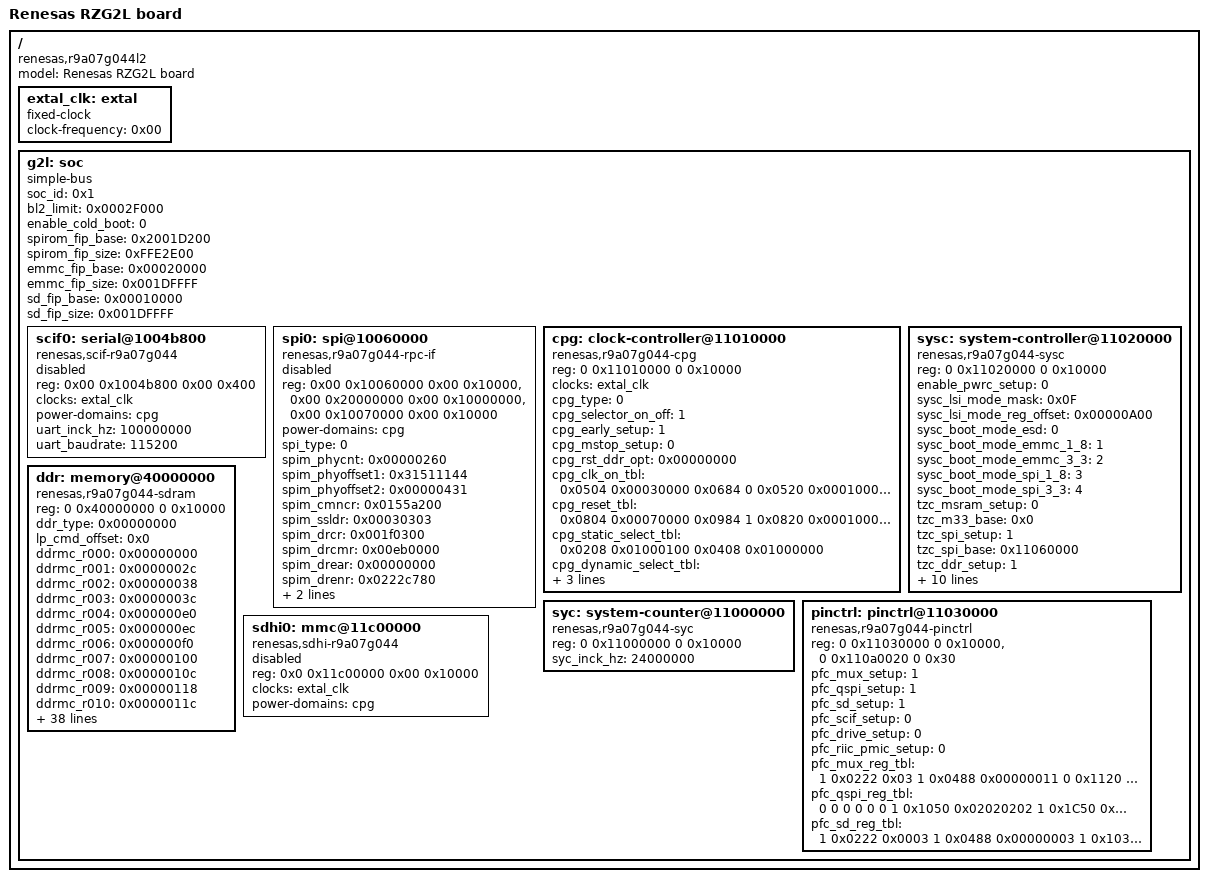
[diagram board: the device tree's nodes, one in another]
// SPDX-License-Identifier: (GPL-2.0-only OR BSD-2-Clause)
/*
 * Copyright (C) 2025 Renesas Electronics Corp.
 */

/dts-v1/;

/ {
	compatible = "renesas,r9a07g044l2", "renesas,r9a07g044";
	model = "Renesas RZG2L board";
	#address-cells = <2>;
	#size-cells = <2>;

	/* clock can be either from exclk or crystal oscillator (XIN/XOUT) */
	extal_clk: extal {
		compatible = "fixed-clock";
		#clock-cells = <0x00>;
		clock-frequency = <0x00>;
		phandle = <0x03>;
	};

	g2l: soc {
		compatible = "simple-bus";
		soc_id = <0x1>;
		bl2_limit = <0x0002F000>;
		enable_cold_boot = <0>;
		spirom_fip_base = <0x2001D200>;
		spirom_fip_size = <0xFFE2E00>;
		emmc_fip_base = <0x00020000>;
		emmc_fip_size = <0x001DFFFF>;
		sd_fip_base = <0x00010000>;
		sd_fip_size = <0x001DFFFF>;
		#address-cells = <0x02>;
		#size-cells = <0x02>;
		ranges;

		scif0: serial@1004b800 {
			compatible = "renesas,scif-r9a07g044";
			reg = <0x00 0x1004b800 0x00 0x400>;
			interrupt-names = "eri", "rxi", "txi", "bri", "dri", "tei";
			clocks = <&extal_clk>;
			clock-names = "fck";
			power-domains = <&cpg>;
			status = "disabled";

			uart_inck_hz = <100000000>;
			uart_baudrate = <115200>;
		};

		spi0: spi@10060000 {
			compatible = "renesas,r9a07g044-rpc-if", "renesas,rzg2l-rpc-if";
			reg = <0x00 0x10060000 0x00 0x10000>,
			      <0x00 0x20000000 0x00 0x10000000>,
			      <0x00 0x10070000 0x00 0x10000>;
			reg-names = "regs", "dirmap", "wbuf";
			power-domains = <&cpg>;
			#address-cells = <1>;
			#size-cells = <0>;
			status = "disabled";

			/* SPI type
			 * [0] = SPI Multi IO
			 * [1] = XSPI
			 */
			spi_type = <0>;

			/* SPI Multi IO specific settings */
			spim_phycnt = <0x00000260>;
			spim_phyoffset1 = <0x31511144>;
			spim_phyoffset2 = <0x00000431>;
			spim_cmncr = <0x0155a200>;
			spim_ssldr = <0x00030303>;
			spim_drcr = <0x001f0300>;
			spim_drcmr = <0x00eb0000>;
			spim_drear = <0x00000000>;
			spim_drenr = <0x0222c780>;
			spim_drdmcr = <0x00000003>;
			spim_drdrenr = <0x00000000>;
		};

		cpg: clock-controller@11010000 {
			compatible = "renesas,r9a07g044-cpg";
			reg = <0 0x11010000 0 0x10000>;
			clocks = <&extal_clk>;
			clock-names = "extal";
			#clock-cells = <2>;
			#reset-cells = <1>;
			#power-domain-cells = <0>;

			cpg_type = <0>;
			cpg_selector_on_off = <1>;
			cpg_early_setup = <1>;
			cpg_mstop_setup = <0>;
			cpg_rst_ddr_opt = <0x00000000>;

			cpg_clk_on_tbl = <
				0x0504 0x00030000
				0x0684
				0
				
				0x0520 0x00010000
				0x06A0
				0
				
				0x052C 0x00030003
				0x06AC
				0
				
				0x0534 0x00060000
				0x06B4
				0
				
				0x0538 0x00010000
				0x06B8
				0
				
				0x053C 0x00010000
				0x06BC
				0
				
				0x0540 0x00010000
				0x06C0
				0
				
				0x0544 0x000F0000
				0x06C4
				0
				
				0x0548 0x003C0000
				0x06C8
				0

				
				0x054C 0x00030000
				0x06CC
				0

				0x0550 0x00030003
				0x06D0
				0
				
				0x0554 0x00ff00ff
				0x06D4
				0
				
				0x0558 0x00070000
				0x06D8
				0
				
				0x055C 0x00030000
				0x06DC
				0
				
				0x0560 0x00010001
				0x06E0
				0
				
				0x0564 0x001f0000
				0x06E4
				0
				
				0x0568 0x003f0000
				0x06E8
				0
				
				0x056C 0x00030000
				0x06EC
				0
				
				0x0570 0x00ff0000
				0x06F0
				0
				
				0x0574 0x00010000
				0x06F4
				0
				
				0x0578 0x000f0000
				0x06F8
				0
				
				0x057C 0x00030000
				0x06FC
				0
				
				0x0580 0x000f0000
				0x0700
				0
				
				0x0584 0x001f0001
				0x0704
				0
				
				0x0588 0x00030000
				0x0708
				0
				
				0x058C 0x00010000
				0x070C
				0
				
				0x0590 0x00070000
				0x0710
				0
				
				0x0594 0x00010000
				0x0714
				0
				
				0x0598 0x00010001
				0x0718
				0
				
				0x05A8 0x00030000
				0x0728
				0
				
				0x05AC 0x00010000
				0x072C
				0
			>;
		
			cpg_reset_tbl = <
				0x0804 0x00070000
				0x0984
				1

				0x0820 0x00010000
				0x09A0
				1

				0x082C 0x00030003
				0x09AC
				1

				0x0834 0x00060000
				0x09B4
				1

				0x0838 0x00010000
				0x09B8
				1

				0x083C 0x00010000
				0x09BC
				1

				0x0840 0x00010000
				0x09C0
				1

				0x0844 0x000f0000
				0x09C4
				1

				0x0848 0x00060000
				0x09C8
				1

				0x084C 0x007F0000
				0x09CC
				1

				0x0850 0x00010001
				0x09D0
				1

				0x0854 0x00030003
				0x09D4
				1

				0x0858 0x00070000
				0x09D8
				1

				0x085C 0x00030000
				0x09DC
				1

				0x0860 0x00030003
				0x09E0
				1

				0x0864 0x00070000
				0x09E4
				1

				0x0868 0x00070000
				0x09E8
				1

				0x086C 0x00010000
				0x09EC
				1

				0x0870 0x000f0000
				0x09F0
				1

				0x0874 0x00010000
				0x09F4
				1

				0x0878 0x000f0000
				0x09F8
				1

				0x087C 0x00030000
				0x09FC
				1

				0x0880 0x000f0000
				0x0A00
				1

				0x0884 0x001f0001
				0x0A04
				1

				0x0888 0x00030000
				0x0A08
				1

				0x088C 0x00010000
				0x0A0C
				1

				0x0890 0x00070000
				0x0A10
				1

				0x0894 0x00030000
				0x0A14
				1

				0x0898 0x00070007
				0x0A18
				1

				0x08A8 0x00030000
				0x0A28
				1

				0x08AC 0x00010000
				0x0A2C
				1
			>;

			cpg_static_select_tbl = <
				0x0208 0x01000100
				0x0408 0x01000000
			>;

			cpg_dynamic_select_tbl = <
				0x021C 0x00010001
				0x0218 0x00110022
			>;

			cpg_pll_tbl = <
				0x0010 0x00010001
				0x0014 0xFAE13203
				0x0018 0x00081000
				0x001C 0x00000011

				0x0020 0x00010001
				0x0024 0x00003e83
				0x0028 0x00082D02
				0x002C 0x00000011
			>;
		};

		sysc: system-controller@11020000 {
			compatible = "renesas,r9a07g044-sysc";
			reg = <0 0x11020000 0 0x10000>;

			enable_pwrc_setup			= <0>;
			sysc_lsi_mode_mask 			= <0x0F>;
			sysc_lsi_mode_reg_offset	= <0x00000A00>;
			sysc_boot_mode_esd 			= <0>;
			sysc_boot_mode_emmc_1_8 	= <1>;
			sysc_boot_mode_emmc_3_3 	= <2>;
			sysc_boot_mode_spi_1_8 		= <3>;
			sysc_boot_mode_spi_3_3 		= <4>;

			/* Security control. */
			tzc_msram_setup = <0>;
			tzc_m33_base	= <0x0>;	// Not used
			tzc_spi_setup	= <1>;
			tzc_spi_base	= <0x11060000>;
			tzc_ddr_setup	= <1>;
			tzc_ddr00_base	= <0x11070000>;
			tzc_ddr01_base	= <0x0>;	// Not used
			tzc_ddr10_base	= <0x0>;	// Not used
			tzc_ddr11_base	= <0x0>;	// Not used
			tzc_pci_setup	= <0>;
			tzc_pci_base	= <0x0>;	// Not used
			tzc_r8_setup	= <0>;
			tzc_r8_base		= <0x0>;	// Not used

			sys_acctl = <
				0x00000000 0x00BB00BB 0x00AAAA88
				0x00000004 0xBBBBBBBB 0xAAAAAAAA
				0x00000008 0x00BBBBBB 0x00AAAAAA
				0x0000000C 0x00BBBBBB 0x00AAAAAA
				0x00000010 0x0B0B00BB 0x0A0A00AA
				0x00000014 0x00000000 0x00000000
				0x00000100 0x0000000F 0x00000008
				0x00000104 0x3FFF3CFF 0x0800C0AA
				0x00000108 0x00FFCFFF 0x00000002
				0x0000010C 0x3FFF3FFF 0x00000000
				0x00000110 0xFFFF0FFF 0x00000000
				0x00000114 0x00000033 0x00000000
				0x00000118 0x0000000F 0x00000000
				0x0000011C 0x0000000C 0x00000008
				0x00000120 0x0000000F 0x00000000
				0x00000124 0x00000000 0x00000000
				0x00000128 0x00000003 0x00000000
				0x0000012C 0x00000000 0x00000000
				0x00000130 0x00000003 0x00000000
				0x00000134 0x00000003 0x00000000
				0x00000138 0x00000003 0x00000000
				0x0000013C 0x00000000 0x00000000
			>;
		};

		syc: system-counter@11000000 {
			compatible = "renesas,r9a07g044-syc";
			reg = <0 0x11000000 0 0x10000>;

			syc_inck_hz = <24000000>;
		};

		pinctrl: pinctrl@11030000 {
			compatible = "renesas,r9a07g044-pinctrl";
			reg = <0 0x11030000 0 0x10000>, <0 0x110a0020 0 0x30>;

			pfc_mux_setup		= <1>;
			pfc_qspi_setup		= <1>;
			pfc_sd_setup		= <1>;
			pfc_scif_setup		= <0>;
			pfc_drive_setup		= <0>;
			pfc_riic_pmic_setup	= <0>;

			pfc_mux_reg_tbl = <
				1 0x0222 0x03
				1 0x0488 0x00000011
				0 0x1120 0x00000101
				0 0x1D10 0x00000000
				0 0x1510 0x00000101

				1 0x0223 0x03
				1 0x048C 0x00000011
				0 0x1128 0x00000101
				0 0x1D18 0x00000000
				0 0x1518 0x00000101

				1 0x0236 0x03
				1 0x04D8 0x00000011
				0 0x11B0 0x00000101
				0 0x1DB0 0x00000000
				0 0x15B0 0x00000101

				1 0x0237 0x07
				1 0x04DC 0x00000111
				0 0x11B8 0x00010101
				0 0x1DB8 0x00000000
				0 0x15B8 0x00010101
			>;

			pfc_qspi_reg_tbl = <
				0 0 0
				0 0 0
				1 0x1050 0x02020202
				1 0x1C50 0x00000000
				1 0x1450 0x01010101

				0 0 0
				0 0 0
				1 0x1058 0x02020202
				1 0x1C58 0x00000000
				1 0x1458 0x01010101

				0 0 0
				0 0 0
				1 0x1060 0x00020202
				1 0x1C60 0x00000000
				1 0x1460 0x00010000
			>;

			pfc_sd_reg_tbl = <
				1 0x0222 0x0003
				1 0x0488 0x00000003
				1 0x1030 0x00020202
				1 0x1C30 0x00000000
				1 0x1430 0x00010101
				1 0x1830 0x00000100

				0 0 0
				0 0 0
				1 0x1038 0x02020202
				1 0x1C38 0x00000000
				1 0x1438 0x01010101
				1 0x1838 0x01010101

				1 0x0223 0x0003
				1 0x048C 0x00000003

				1 0x1040 0x00000202
				1 0x1C40 0x00000000
				1 0x1440 0x00000101
				1 0x1840 0x00000100

				0 0 0
				0 0 0
				1 0x1048 0x02020202
				1 0x1C48 0x00000000
				1 0x1448 0x01010101
				1 0x1848 0x01010101
			>;
		};

		ddr: memory@40000000 {
			compatible = "renesas,r9a07g044-sdram";
			reg = <0 0x40000000 0 0x10000>;

			/* DDR type
			 * [0] = DDR4
			 * [1] = LPDDR4
			 */
			ddr_type = <0x00000000>;

			lp_cmd_offset = <0x0>;

			ddrmc_r000 = <0x00000000>;
			ddrmc_r001 = <0x0000002c>;
			ddrmc_r002 = <0x00000038>;
			ddrmc_r003 = <0x0000003c>;
			ddrmc_r004 = <0x000000e0>;
			ddrmc_r005 = <0x000000ec>;
			ddrmc_r006 = <0x000000f0>;
			ddrmc_r007 = <0x00000100>;
			ddrmc_r008 = <0x0000010c>;
			ddrmc_r009 = <0x00000118>;
			ddrmc_r010 = <0x0000011c>;
			ddrmc_r011 = <0x00000124>;
			ddrmc_r012 = <0x00000128>;
			ddrmc_r013 = <0x0000012c>;
			ddrmc_r014 = <0x00000130>;
			ddrmc_r015 = <0x00000144>;
			ddrmc_r016 = <0x00000148>;
			ddrmc_r017 = <0x0000014c>;
			ddrmc_r018 = <0x00000150>;
			ddrmc_r019 = <0x00000214>;
			ddrmc_r020 = <0x00000218>;
			ddrmc_r021 = <0x00000248>;
			ddrmc_r022 = <0x0000024c>;
			ddrmc_r023 = <0x00000268>;
			ddrmc_r024 = <0x0000026c>;
			ddrmc_r025 = <0x000002c0>;
			ddrmc_r026 = <0x000002c4>;
			ddrmc_r027 = <0x0000061c>;
			ddrmc_r028 = <0x00000638>;
			ddrmc_r029 = <0x00000644>;
			ddrmc_r039 = <0x00000674>;
			ddrmc_r040 = <0x00000678>;
			ddrmc_r043 = <0x00000684>;
			ddrmc_r044 = <0x00000688>;

			swizzle_mc_tbl = <
				0x0000064c 0x00001502
				0x00000650 0x00000a06
				0x00000654 0x170d1112
				0x00000658 0x1900130b
				0x0000065c 0x1f09180c
				0x00000660 0x161c0e14
				0x00000664 0x01101b1a
				0x00000668 0x001d051e
				0x0000066c 0x00000000
			>;

			mc_init_num = <0x000001b4>;

			mc_init_tbl = <
				0x00000000 0x00000a00
				0x00000004 0x00000000
				0x00000008 0x00000000
				0x0000000c 0x00000000
				0x00000010 0x00000000
				0x00000014 0x00000000
				0x00000018 0x00000000
				0x0000001c 0x00000000
				0x00000020 0x00000000
				0x00000024 0x00000000
				0x00000028 0x01000008
				0x0000002c 0x00100100
				0x00000030 0x00027100
				0x00000034 0x00061a80
				0x00000038 0x09180255
				0x0000003c 0x18180000
				0x00000040 0x05050404
				0x00000044 0x00002806
				0x00000048 0x0602001c
				0x0000004c 0x06001c0c
				0x00000050 0x00180806
				0x00000054 0x0400db60
				0x00000058 0x00030305
				0x0000005c 0x01000c0c
				0x00000060 0x0c031801
				0x00000064 0x0100000c
				0x00000068 0x00000101
				0x0000006c 0x00000000
				0x00000070 0x00000000
				0x00000074 0x00040301
				0x00000078 0x000001b8
				0x0000007c 0x00001860
				0x00000080 0x00000005
				0x00000084 0x00140005
				0x00000088 0x01c00255
				0x0000008c 0x000001c0
				0x00000090 0x01000201
				0x00000094 0x80104002
				0x00000098 0x00000000
				0x0000009c 0x00040000
				0x000000a0 0x00000000
				0x000000a4 0x00061800
				0x000000a8 0x000007d0
				0x000000ac 0x00061800
				0x000000b0 0x00061800
				0x000000b4 0x00061800
				0x000000b8 0x00000000
				0x000000bc 0x01000000
				0x000000c0 0x00000000
				0x000000c4 0x00000000
				0x000000c8 0x00000000
				0x000000cc 0x00000000
				0x000000d0 0x00000000
				0x000000d4 0x00000000
				0x000000d8 0x00000000
				0x000000dc 0x00212100
				0x000000e0 0x09070000
				0x000000e4 0x2f0e010a
				0x000000e8 0x00000300
				0x000000ec 0x00010004
				0x000000f0 0x00000800
				0x000000f4 0x00000000
				0x000000f8 0x00000000
				0x000000fc 0x00000000
				0x00000100 0x00000100
				0x00000104 0x00000200
				0x00000108 0x00001000
				0x0000010c 0x00000000
				0x00000110 0x00000000
				0x00000114 0x00000214
				0x00000118 0x00000201
				0x0000011c 0x00000000
				0x00000120 0x00000214
				0x00000124 0x00000201
				0x00000128 0x00000000
				0x0000012c 0x00000000
				0x00000130 0x00000000
				0x00000134 0x00000000
				0x00000138 0x00000000
				0x0000013c 0x00000000
				0x00000140 0x00000000
				0x00000144 0x00000080
				0x00000148 0x00000080
				0x0000014c 0x0000041c
				0x00000150 0x0000041c
				0x00000154 0x01010000
				0x00000158 0x00000000
				0x0000015c 0x00000000
				0x00000160 0x00000000
				0x00000164 0x00000000
				0x00000168 0x00000000
				0x0000016c 0x00000000
				0x00000170 0x00000000
				0x00000174 0x00000000
				0x00000178 0x00000000
				0x0000017c 0x01000200
				0x00000180 0x00010801
				0x00000184 0x00000000
				0x00000188 0x00000000
				0x0000018c 0x00000000
				0x00000190 0x00000000
				0x00000194 0x00000000
				0x00000198 0x00000000
				0x0000019c 0x00000000
				0x000001a0 0x00000000
				0x000001a4 0x00000000
				0x000001a8 0x00000000
				0x000001ac 0x00000000
				0x000001b0 0x00000000
				0x000001b4 0x00000000
				0x000001b8 0x00000008
				0x000001bc 0x006403e8
				0x000001c0 0x00000000
				0x000001c4 0x00000000
				0x000001c8 0x00000000
				0x000001cc 0x15110000
				0x000001d0 0x00040c18
				0x000001d4 0x00bebd03
				0x000001d8 0x0000c350
				0x000001dc 0x00000000
				0x000001e0 0x02000400
				0x000001e4 0x00000080
				0x000001e8 0x00010100
				0x000001ec 0x00010100
				0x000001f0 0x1fff0000
				0x000001f4 0x0003ff00
				0x000001f8 0x3fff2000
				0x000001fc 0x0103ff00
				0x00000200 0xffff0a00
				0x00000204 0x01010001
				0x00000208 0x01010101
				0x0000020c 0x01030101
				0x00000210 0x0c030000
				0x00000214 0x01000000
				0x00000218 0x00000000
				0x0000021c 0x00010000
				0x00000220 0x00000000
				0x00000224 0x00000001
				0x00000228 0x00000000
				0x0000022c 0x00000000
				0x00000230 0x00000000
				0x00000234 0x00000000
				0x00000238 0x00000000
				0x0000023c 0x00000000
				0x00000240 0x00000000
				0x00000244 0x00000000
				0x00000248 0x00000000
				0x0000024c 0x00000000
				0x00000250 0x00000000
				0x00000254 0x00000000
				0x00000258 0x00000000
				0x0000025c 0x00000000
				0x00000260 0x00000000
				0x00000264 0x00000000
				0x00000268 0x00000000
				0x0000026c 0x00000000
				0x00000270 0x00000000
				0x00000274 0x00010000
				0x00000278 0x00000000
				0x0000027c 0x00000800
				0x00000280 0x00000000
				0x00000284 0x00000898
				0x00000288 0x03000000
				0x0000028c 0x00000408
				0x00000290 0x00000000
				0x00000294 0x00000000
				0x00000298 0x00000000
				0x0000029c 0x00000000
				0x000002a0 0x00000000
				0x000002a4 0x00000000
				0x000002a8 0x00000000
				0x000002ac 0x00000000
				0x000002b0 0x00000000
				0x000002b4 0x00000000
				0x000002b8 0x00000000
				0x000002bc 0x06060800
				0x000002c0 0x01000001
				0x000002c4 0x01030200
				0x000002c8 0x03000302
				0x000002cc 0x00000000
				0x000002d0 0x00080801
				0x000002d4 0x00080801
				0x000002d8 0x00070601
				0x000002dc 0x00000000
				0x000002e0 0x000fffff
				0x000002e4 0xffffffff
				0x000002e8 0x000f000f
				0x000002ec 0x00000000
				0x000002f0 0x030fffff
				0x000002f4 0xffffffff
				0x000002f8 0x000f000f
				0x000002fc 0x00000000
				0x00000300 0x030fffff
				0x00000304 0xffffffff
				0x00000308 0x000f000f
				0x0000030c 0x00000000
				0x00000310 0x030fffff
				0x00000314 0xffffffff
				0x00000318 0x000f000f
				0x0000031c 0x00000000
				0x00000320 0x030fffff
				0x00000324 0xffffffff
				0x00000328 0x000f000f
				0x0000032c 0x00000000
				0x00000330 0x030fffff
				0x00000334 0xffffffff
				0x00000338 0x000f000f
				0x0000033c 0x00000000
				0x00000340 0x030fffff
				0x00000344 0xffffffff
				0x00000348 0x000f000f
				0x0000034c 0x00000000
				0x00000350 0x030fffff
				0x00000354 0xffffffff
				0x00000358 0x000f000f
				0x0000035c 0x00000000
				0x00000360 0x030fffff
				0x00000364 0xffffffff
				0x00000368 0x000f000f
				0x0000036c 0x00000000
				0x00000370 0x030fffff
				0x00000374 0xffffffff
				0x00000378 0x000f000f
				0x0000037c 0x00000000
				0x00000380 0x030fffff
				0x00000384 0xffffffff
				0x00000388 0x000f000f
				0x0000038c 0x00000000
				0x00000390 0x030fffff
				0x00000394 0xffffffff
				0x00000398 0x000f000f
				0x0000039c 0x00000000
				0x000003a0 0x030fffff
				0x000003a4 0xffffffff
				0x000003a8 0x000f000f
				0x000003ac 0x00000000
				0x000003b0 0x030fffff
				0x000003b4 0xffffffff
				0x000003b8 0x000f000f
				0x000003bc 0x00000000
				0x000003c0 0x030fffff
				0x000003c4 0xffffffff
				0x000003c8 0x000f000f
				0x000003cc 0x00000000
				0x000003d0 0x030fffff
				0x000003d4 0xffffffff
				0x000003d8 0x000f000f
				0x000003dc 0x00000000
				0x000003e0 0x000fffff
				0x000003e4 0xffffffff
				0x000003e8 0x000f000f
				0x000003ec 0x00000000
				0x000003f0 0x030fffff
				0x000003f4 0xffffffff
				0x000003f8 0x000f000f
				0x000003fc 0x00000000
				0x00000400 0x030fffff
				0x00000404 0xffffffff
				0x00000408 0x000f000f
				0x0000040c 0x00000000
				0x00000410 0x030fffff
				0x00000414 0xffffffff
				0x00000418 0x000f000f
				0x0000041c 0x00000000
				0x00000420 0x030fffff
				0x00000424 0xffffffff
				0x00000428 0x000f000f
				0x0000042c 0x00000000
				0x00000430 0x030fffff
				0x00000434 0xffffffff
				0x00000438 0x000f000f
				0x0000043c 0x00000000
				0x00000440 0x030fffff
				0x00000444 0xffffffff
				0x00000448 0x000f000f
				0x0000044c 0x00000000
				0x00000450 0x030fffff
				0x00000454 0xffffffff
				0x00000458 0x000f000f
				0x0000045c 0x00000000
				0x00000460 0x030fffff
				0x00000464 0xffffffff
				0x00000468 0x000f000f
				0x0000046c 0x00000000
				0x00000470 0x030fffff
				0x00000474 0xffffffff
				0x00000478 0x000f000f
				0x0000047c 0x00000000
				0x00000480 0x030fffff
				0x00000484 0xffffffff
				0x00000488 0x000f000f
				0x0000048c 0x00000000
				0x00000490 0x030fffff
				0x00000494 0xffffffff
				0x00000498 0x000f000f
				0x0000049c 0x00000000
				0x000004a0 0x030fffff
				0x000004a4 0xffffffff
				0x000004a8 0x000f000f
				0x000004ac 0x00000000
				0x000004b0 0x030fffff
				0x000004b4 0xffffffff
				0x000004b8 0x000f000f
				0x000004bc 0x00000000
				0x000004c0 0x030fffff
				0x000004c4 0xffffffff
				0x000004c8 0x000f000f
				0x000004cc 0x00000000
				0x000004d0 0x030fffff
				0x000004d4 0xffffffff
				0x000004d8 0x000f000f
				0x000004dc 0x00000000
				0x000004e0 0x000fffff
				0x000004e4 0xffffffff
				0x000004e8 0x000f000f
				0x000004ec 0x00000000
				0x000004f0 0x030fffff
				0x000004f4 0xffffffff
				0x000004f8 0x000f000f
				0x000004fc 0x00000000
				0x00000500 0x030fffff
				0x00000504 0xffffffff
				0x00000508 0x000f000f
				0x0000050c 0x00000000
				0x00000510 0x030fffff
				0x00000514 0xffffffff
				0x00000518 0x000f000f
				0x0000051c 0x00000000
				0x00000520 0x030fffff
				0x00000524 0xffffffff
				0x00000528 0x000f000f
				0x0000052c 0x00000000
				0x00000530 0x030fffff
				0x00000534 0xffffffff
				0x00000538 0x000f000f
				0x0000053c 0x00000000
				0x00000540 0x030fffff
				0x00000544 0xffffffff
				0x00000548 0x000f000f
				0x0000054c 0x00000000
				0x00000550 0x030fffff
				0x00000554 0xffffffff
				0x00000558 0x000f000f
				0x0000055c 0x00000000
				0x00000560 0x030fffff
				0x00000564 0xffffffff
				0x00000568 0x000f000f
				0x0000056c 0x00000000
				0x00000570 0x030fffff
				0x00000574 0xffffffff
				0x00000578 0x000f000f
				0x0000057c 0x00000000
				0x00000580 0x030fffff
				0x00000584 0xffffffff
				0x00000588 0x000f000f
				0x0000058c 0x00000000
				0x00000590 0x030fffff
				0x00000594 0xffffffff
				0x00000598 0x000f000f
				0x0000059c 0x00000000
				0x000005a0 0x030fffff
				0x000005a4 0xffffffff
				0x000005a8 0x000f000f
				0x000005ac 0x00000000
				0x000005b0 0x030fffff
				0x000005b4 0xffffffff
				0x000005b8 0x000f000f
				0x000005bc 0x00000000
				0x000005c0 0x030fffff
				0x000005c4 0xffffffff
				0x000005c8 0x000f000f
				0x000005cc 0x00000000
				0x000005d0 0x030fffff
				0x000005d4 0xffffffff
				0x000005d8 0x000f000f
				0x000005dc 0x03000000
				0x000005e0 0x03030303
				0x000005e4 0x03030303
				0x000005e8 0x03030303
				0x000005ec 0x00030303
				0x000005f0 0x02020064
				0x000005f4 0x02020202
				0x000005f8 0x02020202
				0x000005fc 0x02020202
				0x00000600 0x00010202
				0x00000604 0x01010064
				0x00000608 0x01010101
				0x0000060c 0x01010101
				0x00000610 0x01010101
				0x00000614 0x00020101
				0x00000618 0x00000064
				0x0000061c 0x00000006
				0x00000620 0x000007d0
				0x00000624 0x00000032
				0x00000628 0x00000200
				0x0000062c 0x00000200
				0x00000630 0x00000000
				0x00000634 0x00000000
				0x00000638 0x030b0205
				0x0000063c 0x00200308
				0x00000640 0x00000000
				0x00000644 0x0a000200
				0x00000648 0x000c000a
				0x0000064c 0x00000000
				0x00000650 0x00000000
				0x00000654 0x00000000
				0x00000658 0x00000000
				0x0000065c 0x00000000
				0x00000660 0x00000000
				0x00000664 0x00000000
				0x00000668 0x00000000
				0x0000066c 0x00000000
				0x00000670 0x0000000f
				0x00000674 0x037204e2
				0x00000678 0x576e08e8
				0x0000067c 0x00003c22
				0x00000680 0x22227822
				0x00000684 0x00123312
				0x00000688 0x00000000
				0x0000068c 0x00000000
				0x00000690 0x00000000
				0x00000694 0x00000000
				0x00000698 0x00000000
				0x0000069c 0x00000000
				0x000006a0 0x00000000
				0x000006a4 0x00000000
				0x000006a8 0x00000000
				0x000006ac 0x00000000
				0x000006b0 0x00000000
				0x000006b4 0x00000000
				0x000006b8 0x00000000
				0x000006bc 0x00000000
				0x000006c0 0x00000000
				0x000006c4 0x00000000
				0x000006c8 0x00000000
				0x000006cc 0x00000000
			>;

			swizzle_phy_tbl = <
				0x0000012c 0x00000000
				0x000000a8 0x1b03150e
				0x0000012c 0x00000001
				0x000000a8 0x16001706
				0x0000012c 0x00000002
				0x000000a8 0x0d050807
				0x0000012c 0x00000003
				0x000000a8 0x1901020b
				0x0000012c 0x00000004
				0x000000a8 0x13121110
				0x0000012c 0x00000005
				0x000000a8 0x0f090418
				0x0000012c 0x00000006
				0x000000a8 0x1a0a1d14
				0x0000012c 0x00000007
				0x000000a8 0x001e1c0c
			>;

			mc_phy_settings_tbl = <
				0x00000678 0x576e08e8
				0x0000067c 0x00003c22
				0x00000680 0x22227822
				0x00000684 0x00123312
			>;

			mc_odt_pins_tbl = <
				0x00000001
				0x00000002
				0x00000000
				0x00000000
			>;

			mc_mr1_tbl = <
				0x00000706
				0x00000200
			>;

			mc_mr2_tbl = <
				0x00000e00
				0x00000000
			>;

			mc_mr5_tbl = <
				0x000001c0
				0x000001c0
			>;

			mc_mr6_tbl = <
				0x0000007f
				0x0000001c
			>;
		};

		sdhi0: mmc@11c00000 {
			compatible = "renesas,sdhi-r9a07g044",
				     "renesas,rcar-gen3-sdhi";
			reg = <0x0 0x11c00000 0x00 0x10000>;
			clocks = <&extal_clk>;
			clock-names = "core", "clkh", "cd", "aclk";
			power-domains = <&cpg>;
			status = "disabled";
		};
	};
};
